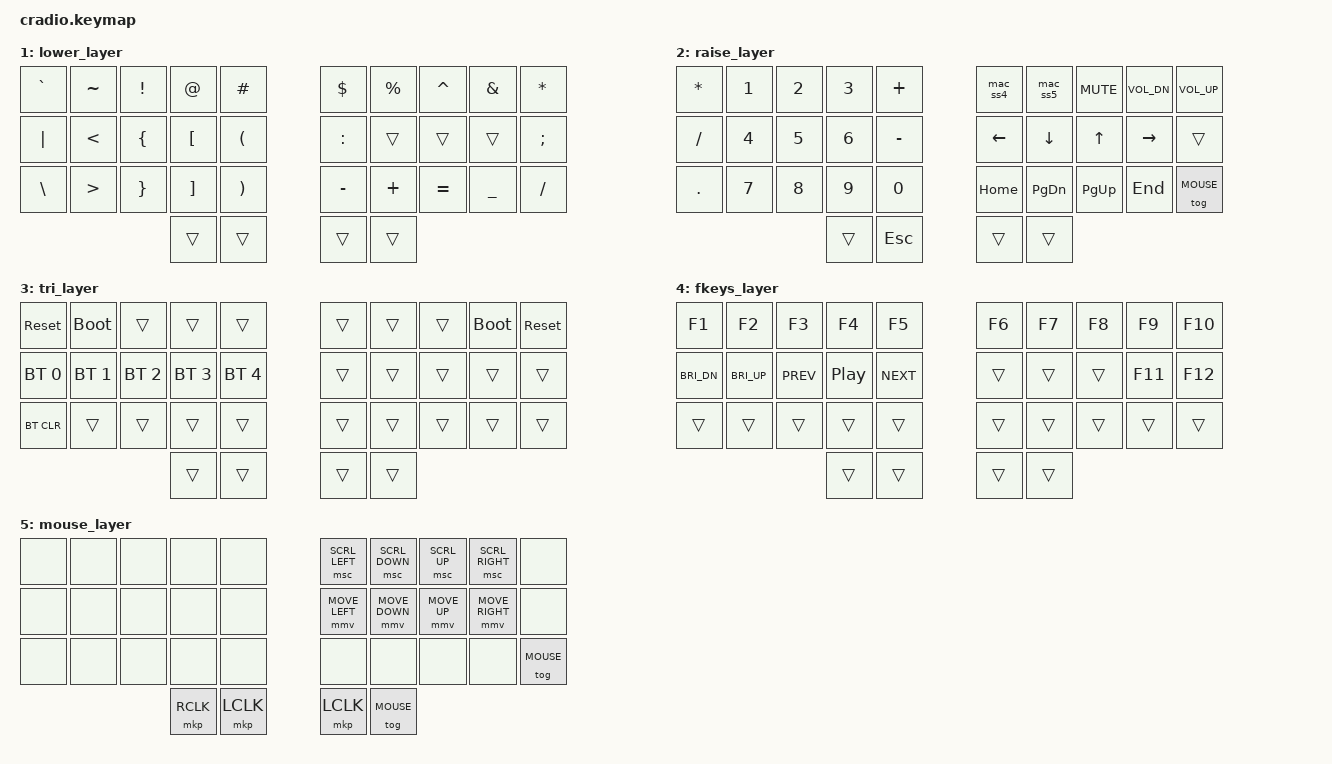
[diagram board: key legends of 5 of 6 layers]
/*
 * Cradio/Ferris Sweep Keymap
 *
 * Features:
 * - Home row mods: A/S/D/F = SFT/ALT/CTL/GUI, J/K/L/' = GUI/CTL/ALT/SFT
 * - Hold Z for F-keys layer
 * - Left thumb: TAB/Lower (symbols with paired brackets)
 * - Right thumb: Backspace/Raise (calculator numpad + nav + media)
 * - Tri-layer (both thumbs): System controls + Bluetooth
 * - Mouse layer: hold Raise + tap "/" to toggle keyboard mouse (move/click/scroll)
 * - Ukrainian letter support:
 *   - Hold P (з) → [ (х)
 *   - Hold . → ] (ї)
 *   - Combo O+P → [ (х)
 *   - Combo L+' → ; (ж)
 *   - Combo U+I → +
 *   - Combo M+, → -
 *   - Combo E+R → !
 *   - Combo C+V → ?
 */

#include <behaviors.dtsi>
#include <dt-bindings/zmk/keys.h>
#include <dt-bindings/zmk/bt.h>

// Pointer tuning: top speed in px/s (default 600) and scroll speed (default 10)
#define ZMK_POINTING_DEFAULT_MOVE_VAL 1500
#define ZMK_POINTING_DEFAULT_SCRL_VAL 20

#include <dt-bindings/zmk/pointing.h>

// Reach top speed faster for a snappier feel (defaults: 300ms, exponent 1)
&mmv {
    time-to-max-speed-ms = <200>;
    acceleration-exponent = <1>;
};

// Layer definitions
#define BASE 0
#define LOWER 1    // Symbols layer (left thumb)
#define RAISE 2    // Numbers/navigation layer (right thumb)
#define TRI 3      // Tri-layer (both thumbs) - system controls
#define FKEYS 4    // F-keys layer (hold Z)
#define MOUSE 5    // Mouse layer (toggle: RAISE + bottom-right "/")

// Home row mod macros (matching default Cradio)
#define HRML(k1,k2,k3,k4) &ht LSHFT k1  &ht LALT k2  &ht LCTRL k3  &ht LGUI k4
#define HRMR(k1,k2,k3,k4) &ht RGUI k1   &ht RCTRL k2  &ht RALT k3  &ht RSHFT k4

/ {
    macros {
        // Mac screenshot selection (Cmd+Shift+4)
        mac_ss4: mac_screenshot_4 {
            compatible = "zmk,behavior-macro";
            #binding-cells = <0>;
            bindings = <&kp LG(LS(N4))>;
        };
        // Mac screenshot menu (Cmd+Shift+5)
        mac_ss5: mac_screenshot_5 {
            compatible = "zmk,behavior-macro";
            #binding-cells = <0>;
            bindings = <&kp LG(LS(N5))>;
        };
    };

    combos {
        compatible = "zmk,combos";
        // Ukrainian х: O+P → [ (щ+з → х in Ukrainian layout)
        combo_ua_kha {
            timeout-ms = <50>;
            key-positions = <8 9>;
            bindings = <&kp LBKT>;
            layers = <BASE>;
        };
        // Ukrainian ж: L+' → ; (д+є → ж in Ukrainian layout)
        combo_ua_zhe {
            timeout-ms = <50>;
            key-positions = <18 19>;
            bindings = <&kp SEMI>;
            layers = <BASE>;
        };
        // U+I → +
        combo_plus {
            timeout-ms = <50>;
            key-positions = <6 7>;
            bindings = <&kp KP_PLUS>;
            layers = <BASE>;
        };
        // M+, → -
        combo_minus {
            timeout-ms = <50>;
            key-positions = <26 27>;
            bindings = <&kp KP_MINUS>;
            layers = <BASE>;
        };
        // E+R → !
        combo_excl {
            timeout-ms = <50>;
            key-positions = <2 3>;
            bindings = <&kp EXCL>;
            layers = <BASE>;
        };
        // C+V → ? (sends NON_US_BACKSLASH, remapped to ? via Karabiner per layout)
        combo_qmark {
            timeout-ms = <50>;
            key-positions = <22 23>;
            bindings = <&kp NON_US_BACKSLASH>;
            layers = <BASE>;
        };
    };

    behaviors {
        // Home row mods (matching default Cradio exactly)
        ht: hold_tap {
            compatible = "zmk,behavior-hold-tap";
            #binding-cells = <2>;
            flavor = "tap-preferred";
            tapping-term-ms = <220>;
            quick-tap-ms = <150>;
            require-prior-idle-ms = <100>;
            bindings = <&kp>, <&kp>;
        };

        // Hold-tap for Z key - tap: Z, hold: F-keys layer
        lt_z: layer_tap_z {
            compatible = "zmk,behavior-hold-tap";
            #binding-cells = <2>;
            flavor = "tap-preferred";
            tapping-term-ms = <220>;
            quick-tap-ms = <150>;
            require-prior-idle-ms = <100>;
            bindings = <&mo>, <&kp>;
        };

        // Ukrainian: tap P (з) → hold [ (х)
        ua_ze_kha: ukrainian_ze_kha {
            compatible = "zmk,behavior-hold-tap";
            #binding-cells = <2>;
            flavor = "tap-preferred";
            tapping-term-ms = <220>;
            require-prior-idle-ms = <100>;
            bindings = <&kp>, <&kp>;
        };

        // Ukrainian: tap . → hold ] (ї)
        ua_yi: ukrainian_yi {
            compatible = "zmk,behavior-hold-tap";
            #binding-cells = <2>;
            flavor = "tap-preferred";
            tapping-term-ms = <220>;
            require-prior-idle-ms = <100>;
            bindings = <&kp>, <&kp>;
        };
    };

    // Tri-layer: activates TRI layer when both LOWER and RAISE are held
    conditional_layers {
        compatible = "zmk,conditional-layers";
        tri_layer {
            if-layers = <LOWER RAISE>;
            then-layer = <TRI>;
        };
    };

    keymap {
        compatible = "zmk,keymap";

        // Base QWERTY layer with home row mods
        // ╭─────────────────────────────────────────────╮ ╭─────────────────────────────────────────────╮
        // │  Q  │  W  │  E  │  R  │  T  │               │  Y  │  U  │  I  │  O  │  P(з/х) │
        // │A/SFT│S/ALT│D/CTL│F/GUI│  G  │               │  H  │J/GUI│K/CTL│L/ALT│ '/SFT   │
        // │Z/FKY│  X  │  C  │  V  │  B  │               │  N  │  M  │  ,  │.(ї) │    /    │
        // ╰───────────────────╮TAB/LWR│ ENT │       │ SPC │BSPC/RSE╭───────────────────╯
        //                     ╰───────────╯         ╰─────────────╯
        base_layer {
            bindings = <
                &kp Q              &kp W        &kp E         &kp R         &kp T      &kp Y  &kp U         &kp I          &kp O         &ua_ze_kha LBKT P
                HRML(A,            S,           D,            F)            &kp G      &kp H  HRMR(J,       K,             L,            SQT)
                &lt_z FKEYS Z      &kp X        &kp C         &kp V         &kp B      &kp N  &kp M         &kp COMMA      &ua_yi RBKT DOT &kp FSLH
                                                &lt LOWER TAB  &kp RET                &kp SPACE  &lt RAISE BSPC
            >;
        };

        // Lower layer (SYMBOLS) - paired brackets on left
        // ╭─────────────────────────────────────────────╮ ╭─────────────────────────────────────────────╮
        // │  `  │  ~  │  !  │  @  │  #  │               │  $  │  %  │  ^  │  &  │  *  │
        // │  |  │  <  │  {  │  [  │  (  │               │  :  │     │     │     │  ;  │
        // │  \  │  >  │  }  │  ]  │  )  │               │  -  │  +  │  =  │  _  │  /  │
        // ╰───────────────────╮     │     │         │     │     ╭───────────────────╯
        //                     ╰───────────╯         ╰───────────╯
        lower_layer {
            bindings = <
                &kp GRAVE  &kp TILDE  &kp EXCL   &kp AT     &kp HASH       &kp DLLR   &kp PRCNT  &kp CARET  &kp AMPS   &kp ASTRK
                &kp PIPE   &kp LT     &kp LBRC   &kp LBKT   &kp LPAR       &kp COLON  &trans     &trans     &trans     &kp SEMI
                &kp BSLH   &kp GT     &kp RBRC   &kp RBKT   &kp RPAR       &kp MINUS  &kp PLUS   &kp EQUAL  &kp UNDER  &kp FSLH
                                      &trans     &trans                    &trans     &trans
            >;
        };

        // Raise layer (NUMBERS + NAV + MEDIA) - calculator numpad on left
        // ╭─────────────────────────────────────────────╮ ╭─────────────────────────────────────────────╮
        // │  *  │  1  │  2  │  3  │  +  │               │ SS4 │ SS5 │MUTE │VOL- │VOL+ │
        // │  /  │  4  │  5  │  6  │  -  │               │LEFT │DOWN │ UP  │RIGHT│     │
        // │  .  │  7  │  8  │  9  │  0  │               │HOME │PGDN │PGUP │ END │MOUS │
        // ╰───────────────────╮     │     │         │     │     ╭───────────────────╯
        //                     ╰───────────╯         ╰───────────╯
        raise_layer {
            bindings = <
                &kp ASTRK  &kp N1     &kp N2     &kp N3     &kp PLUS        &mac_ss4      &mac_ss5      &kp C_MUTE    &kp C_VOL_DN  &kp C_VOL_UP
                &kp FSLH   &kp N4     &kp N5     &kp N6     &kp MINUS       &kp LEFT      &kp DOWN      &kp UP        &kp RIGHT     &trans
                &kp DOT    &kp N7     &kp N8     &kp N9     &kp N0          &kp HOME      &kp PG_DN     &kp PG_UP     &kp END       &tog MOUSE
                                      &trans     &kp ESC                    &trans        &trans
            >;
        };

        // Tri-layer (activated by holding both thumbs)
        // System controls and Bluetooth
        // ╭─────────────────────────────────────────────╮ ╭─────────────────────────────────────────────╮
        // │RESET│BTLDR│     │     │     │               │     │     │     │BTLDR│RESET│
        // │ BT0 │ BT1 │ BT2 │ BT3 │ BT4 │               │     │     │     │     │     │
        // │BTCLR│     │     │     │     │               │     │     │     │     │     │
        // ╰───────────────────╮     │     │         │     │     ╭───────────────────╯
        //                     ╰───────────╯         ╰───────────╯
        tri_layer {
            bindings = <
                &sys_reset    &bootloader   &trans        &trans        &trans          &trans  &trans  &trans  &bootloader  &sys_reset
                &bt BT_SEL 0  &bt BT_SEL 1  &bt BT_SEL 2  &bt BT_SEL 3  &bt BT_SEL 4    &trans  &trans  &trans  &trans       &trans
                &bt BT_CLR    &trans        &trans        &trans        &trans          &trans  &trans  &trans  &trans       &trans
                                            &trans        &trans                        &trans  &trans
            >;
        };

        // F-keys layer (activated by holding Z)
        // macOS function keys: brightness, media playback
        // ╭─────────────────────────────────────────────╮ ╭─────────────────────────────────────────────╮
        // │ F1  │ F2  │ F3  │ F4  │ F5  │               │ F6  │ F7  │ F8  │ F9  │ F10 │
        // │ BRI-│ BRI+│PREV │PLAY │NEXT │               │     │     │     │ F11 │ F12 │
        // │     │     │     │     │     │               │     │     │     │     │     │
        // ╰───────────────────╮     │     │         │     │     ╭───────────────────╯
        //                     ╰───────────╯         ╰───────────╯
        fkeys_layer {
            bindings = <
                &kp F1            &kp F2            &kp F3      &kp F4    &kp F5       &kp F6   &kp F7  &kp F8  &kp F9   &kp F10
                &kp C_BRI_DN      &kp C_BRI_UP      &kp C_PREV  &kp C_PP  &kp C_NEXT   &trans   &trans  &trans  &kp F11  &kp F12
                &trans            &trans            &trans      &trans    &trans       &trans   &trans  &trans  &trans   &trans
                                                    &trans      &trans                 &trans   &trans
            >;
        };

        // Mouse layer (POINTER) - toggle ON: hold RAISE + tap bottom-right "/";  toggle OFF: tap "/" (or right-outer thumb)
        // Move = right-hand HJKL (Vim positions), Scroll = row above, Click = thumbs (inner = Left, left-outer = Right)
        // ╭─────────────────────────────────────────────╮ ╭─────────────────────────────────────────────╮
        // │     │     │     │     │     │               │SCR← │SCR↓ │SCR↑ │SCR→ │     │
        // │     │     │     │     │     │               │MOV← │MOV↓ │MOV↑ │MOV→ │     │
        // │     │     │     │     │     │               │     │     │     │     │ OFF │
        // ╰───────────────────╮RCLK │LCLK │       │LCLK │ OFF ╭───────────────────╯
        //                     ╰───────────╯         ╰───────────╯
        mouse_layer {
            bindings = <
                &none  &none  &none  &none  &none    &msc SCRL_LEFT  &msc SCRL_DOWN  &msc SCRL_UP  &msc SCRL_RIGHT  &none
                &none  &none  &none  &none  &none    &mmv MOVE_LEFT  &mmv MOVE_DOWN  &mmv MOVE_UP  &mmv MOVE_RIGHT  &none
                &none  &none  &none  &none  &none    &none           &none           &none         &none            &tog MOUSE
                                     &mkp RCLK  &mkp LCLK             &mkp LCLK  &tog MOUSE
            >;
        };
    };
};
